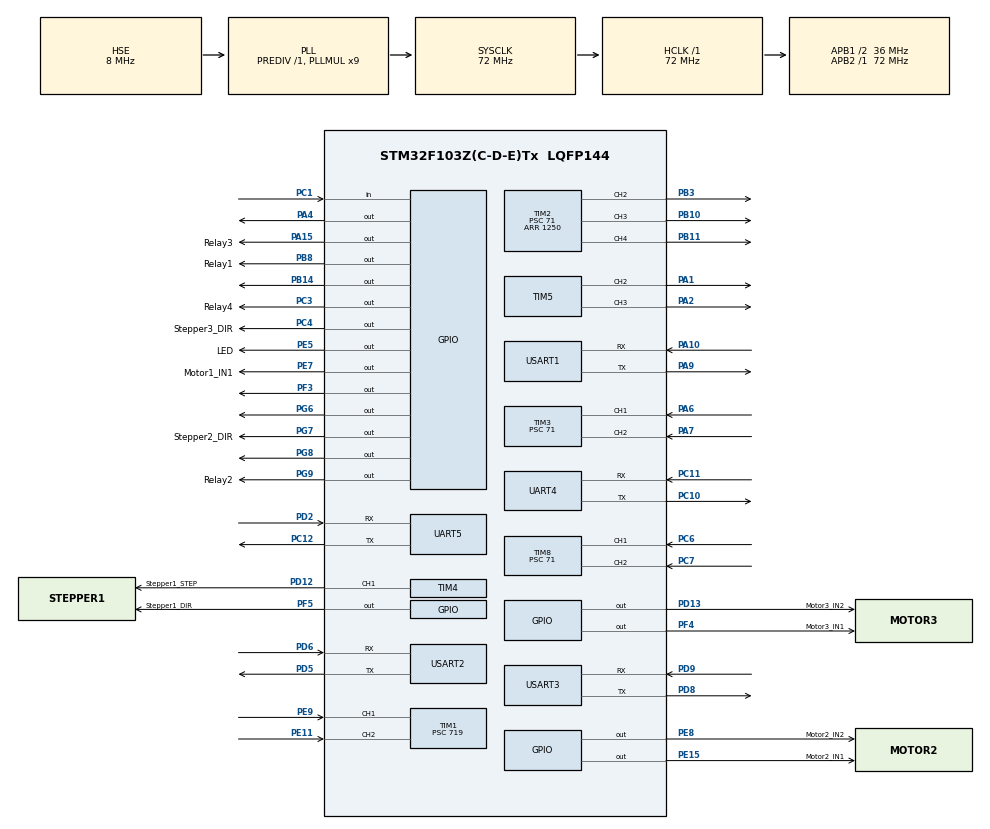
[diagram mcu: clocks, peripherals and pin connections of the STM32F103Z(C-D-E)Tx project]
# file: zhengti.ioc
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Mcu.Family=STM32F1
Mcu.Name=STM32F103Z(C-D-E)Tx
Mcu.Package=LQFP144
NVIC.PriorityGroup=NVIC_PRIORITYGROUP_4
NVIC.TIM2_IRQn=true\:0\:0\:false\:false\:true\:true\:true\:true
NVIC.TIM3_IRQn=true\:0\:0\:false\:false\:true\:true\:true\:true
NVIC.TIM4_IRQn=true\:0\:0\:false\:false\:true\:true\:true\:true
NVIC.TIM6_IRQn=true\:0\:0\:false\:false\:true\:true\:true\:true
NVIC.TIM7_IRQn=true\:0\:0\:false\:false\:true\:true\:true\:true
NVIC.TIM8_UP_IRQn=true\:0\:0\:false\:false\:true\:true\:true\:true
NVIC.USART1_IRQn=true\:0\:0\:false\:false\:true\:true\:true\:true
NVIC.USART2_IRQn=true\:0\:0\:false\:false\:true\:true\:true\:true
NVIC.USART3_IRQn=true\:0\:0\:false\:false\:true\:true\:true\:true
OSC_IN.Mode=HSE-External-Oscillator
OSC_IN.Signal=RCC_OSC_IN
OSC_OUT.Mode=HSE-External-Oscillator
OSC_OUT.Signal=RCC_OSC_OUT
PA1.Signal=S_TIM5_CH2
PA10.Mode=Asynchronous
PA10.Signal=USART1_RX
PA13.Mode=Serial_Wire
PA13.Signal=SYS_JTMS-SWDIO
PA14.Mode=Serial_Wire
PA14.Signal=SYS_JTCK-SWCLK
PA15.GPIO_Label=Relay3
PA15.Signal=GPIO_Output
PA2.Signal=S_TIM5_CH3
PA4.Signal=GPIO_Output
PA6.GPIO_PuPd=GPIO_PULLUP
PA6.Signal=S_TIM3_CH1
PA7.GPIO_PuPd=GPIO_PULLUP
PA7.Signal=S_TIM3_CH2
PA9.Mode=Asynchronous
PA9.Signal=USART1_TX
PB10.Signal=S_TIM2_CH3
PB11.Signal=S_TIM2_CH4
PB14.Signal=GPIO_Output
PB3.Signal=S_TIM2_CH2
PB8.GPIO_Label=Relay1
PB8.Signal=GPIO_Output
PC1.Signal=GPIO_Input
PC10.Mode=Asynchronous
PC10.Signal=UART4_TX
PC11.Mode=Asynchronous
PC11.Signal=UART4_RX
PC12.Mode=Asynchronous
PC12.Signal=UART5_TX
PC3.GPIO_Label=Relay4
PC3.Signal=GPIO_Output
PC4.GPIO_Label=Stepper3_DIR
PC4.Signal=GPIO_Output
PC6.GPIO_PuPd=GPIO_PULLUP
PC6.Signal=S_TIM8_CH1
PC7.GPIO_PuPd=GPIO_PULLUP
PC7.Signal=S_TIM8_CH2
PD12.GPIO_Label=Stepper1_STEP
PD12.Signal=S_TIM4_CH1
PD13.GPIO_Label=Motor3_IN2
PD13.Signal=GPIO_Output
PD2.Mode=Asynchronous
PD2.Signal=UART5_RX
PD5.Mode=Asynchronous
PD5.Signal=USART2_TX
PD6.Mode=Asynchronous
PD6.Signal=USART2_RX
PD8.Mode=Asynchronous
PD8.Signal=USART3_TX
PD9.Mode=Asynchronous
PD9.Signal=USART3_RX
PE11.GPIO_PuPd=GPIO_PULLUP
PE11.Signal=S_TIM1_CH2
PE15.GPIO_Label=Motor2_IN1
PE15.Signal=GPIO_Output
PE5.GPIO_Label=LED
PE5.Signal=GPIO_Output
PE7.GPIO_Label=Motor1_IN1
PE7.Signal=GPIO_Output
PE8.GPIO_Label=Motor2_IN2
PE8.Signal=GPIO_Output
PE9.GPIO_PuPd=GPIO_PULLUP
PE9.Signal=S_TIM1_CH1
PF3.Signal=GPIO_Output
PF4.GPIO_Label=Motor3_IN1
PF4.Signal=GPIO_Output
PF5.GPIO_Label=Stepper1_DIR
PF5.Signal=GPIO_Output
PG6.Signal=GPIO_Output
PG7.GPIO_Label=Stepper2_DIR
PG7.Signal=GPIO_Output
PG8.Signal=GPIO_Output
PG9.GPIO_Label=Relay2
PG9.Signal=GPIO_Output
ProjectManager.HeapSize=0x200
ProjectManager.StackSize=0x400
ProjectManager.TargetToolchain=MDK-ARM V5.32
RCC.AHBFreq_Value=72000000
RCC.APB1CLKDivider=RCC_HCLK_DIV2
RCC.APB1Freq_Value=36000000
RCC.APB1TimFreq_Value=72000000
RCC.APB2Freq_Value=72000000
RCC.APB2TimFreq_Value=72000000
RCC.HCLKFreq_Value=72000000
RCC.PLLMUL=RCC_PLL_MUL9
RCC.PLLSourceVirtual=RCC_PLLSOURCE_HSE
RCC.SYSCLKFreq_VALUE=72000000
RCC.SYSCLKSource=RCC_SYSCLKSOURCE_PLLCLK
RCC.USBFreq_Value=72000000
SH.S_TIM1_CH1.0=TIM1_CH1,Encoder_Interface
SH.S_TIM1_CH2.0=TIM1_CH2,Encoder_Interface
SH.S_TIM2_CH2.0=TIM2_CH2,PWM Generation2 CH2
SH.S_TIM2_CH3.0=TIM2_CH3,PWM Generation3 CH3
SH.S_TIM2_CH4.0=TIM2_CH4,PWM Generation4 CH4
SH.S_TIM3_CH1.0=TIM3_CH1,Encoder_Interface
SH.S_TIM3_CH2.0=TIM3_CH2,Encoder_Interface
SH.S_TIM4_CH1.0=TIM4_CH1,PWM Generation1 CH1
SH.S_TIM5_CH2.0=TIM5_CH2,PWM Generation2 CH2
SH.S_TIM5_CH3.0=TIM5_CH3,PWM Generation3 CH3
SH.S_TIM8_CH1.0=TIM8_CH1,Encoder_Interface
SH.S_TIM8_CH2.0=TIM8_CH2,Encoder_Interface
TIM1.Period=99
TIM1.Prescaler=719
TIM2.Channel-PWM\ Generation2\ CH2=TIM_CHANNEL_2
TIM2.Channel-PWM\ Generation3\ CH3=TIM_CHANNEL_3
TIM2.Channel-PWM\ Generation4\ CH4=TIM_CHANNEL_4
TIM2.Period=1250
TIM2.Prescaler=71
TIM2.Pulse-PWM\ Generation3\ CH3=625
TIM3.Period=625
TIM3.Prescaler=71
TIM4.AutoReloadPreload=TIM_AUTORELOAD_PRELOAD_ENABLE
TIM4.Channel-PWM\ Generation1\ CH1=TIM_CHANNEL_1
TIM4.Period=1000-1
TIM4.Prescaler=72-1
TIM4.Pulse-PWM\ Generation1\ CH1=500
TIM5.Channel-PWM\ Generation2\ CH2=TIM_CHANNEL_2
TIM5.Channel-PWM\ Generation3\ CH3=TIM_CHANNEL_3
TIM6.Period=9999
TIM6.Prescaler=7199
TIM7.Period=59999
TIM7.Prescaler=7199
TIM8.AutoReloadPreload=TIM_AUTORELOAD_PRELOAD_ENABLE
TIM8.Period=1250
TIM8.Prescaler=71
UART4.VirtualMode=Asynchronous
UART5.VirtualMode=Asynchronous
USART1.VirtualMode=VM_ASYNC
USART2.VirtualMode=VM_ASYNC
USART3.VirtualMode=VM_ASYNC
VP_TIM2_VS_ClockSourceINT.Mode=Internal
VP_TIM4_VS_ClockSourceINT.Mode=Internal
VP_TIM5_VS_ClockSourceINT.Mode=Internal
VP_TIM6_VS_ClockSourceINT.Mode=Enable_Timer
VP_TIM7_VS_ClockSourceINT.Mode=Enable_Timer
board=custom

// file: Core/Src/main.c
/* USER CODE BEGIN Header */
/**
  ******************************************************************************
  * @file           : main.c
  * @brief          : Main program body
  ******************************************************************************
  * @attention
  *
  * Copyright (c) 2026 STMicroelectronics.
  * All rights reserved.
  *
  * This software is licensed under terms that can be found in the LICENSE file
  * in the root directory of this software component.
  * If no LICENSE file comes with this software, it is provided AS-IS.
  *
  ******************************************************************************
  */
/* USER CODE END Header */
#include "main.h"
#include "tim.h"
#include "usart.h"
#include "gpio.h"

/* USER CODE BEGIN Includes */
#include "value.h"
#include "task.h"
/* USER CODE END Includes */

void SystemClock_Config(void);

int main(void)
{

  /* USER CODE BEGIN 1 */
  uint32_t tick;
  /* USER CODE END 1 */

  /* MCU Configuration--------------------------------------------------------*/

  /* Reset of all peripherals, Initializes the Flash interface and the Systick. */
  HAL_Init();

  /* Configure the system clock */
  SystemClock_Config();

  /* Initialize all configured peripherals */
  MX_GPIO_Init();
  MX_TIM1_Init();
  MX_TIM2_Init();
  MX_TIM3_Init();
  MX_TIM6_Init();
  MX_TIM7_Init();
  MX_TIM8_Init();
  MX_TIM4_Init();
  MX_USART1_UART_Init();
  MX_USART2_UART_Init();
  MX_USART3_UART_Init();
  MX_TIM5_Init();
  MX_UART4_Init();
  MX_UART5_Init();
  /* USER CODE BEGIN 2 */

  INIT_ALL();

  tick = HAL_GetTick();

  /* USER CODE END 2 */

  /* Infinite loop */
  /* USER CODE BEGIN WHILE */
  while (1)
  {
    /* 50Hz 任务调度 */
    if (HAL_GetTick() - tick < TASK_PERIOD_MS) continue;
    tick = HAL_GetTick();

    Task_Uart1();
    Task_Process();

    /* USER CODE END WHILE */

  }
}

void SystemClock_Config(void)
{
  RCC_OscInitTypeDef RCC_OscInitStruct = {0};
  RCC_ClkInitTypeDef RCC_ClkInitStruct = {0};

  /** Initializes the RCC Oscillators according to the specified parameters
  * in the RCC_OscInitTypeDef structure.
  */
  RCC_OscInitStruct.OscillatorType = RCC_OSCILLATORTYPE_HSE;
  RCC_OscInitStruct.HSEState = RCC_HSE_ON;
  RCC_OscInitStruct.HSEPredivValue = RCC_HSE_PREDIV_DIV1;
  RCC_OscInitStruct.HSIState = RCC_HSI_ON;
  RCC_OscInitStruct.PLL.PLLState = RCC_PLL_ON;
  RCC_OscInitStruct.PLL.PLLSource = RCC_PLLSOURCE_HSE;
  RCC_OscInitStruct.PLL.PLLMUL = RCC_PLL_MUL9;
  if (HAL_RCC_OscConfig(&RCC_OscInitStruct) != HAL_OK)
  {
    Error_Handler();
  }

  /** Initializes the CPU, AHB and APB buses clocks
  */
  RCC_ClkInitStruct.ClockType = RCC_CLOCKTYPE_HCLK|RCC_CLOCKTYPE_SYSCLK
                              |RCC_CLOCKTYPE_PCLK1|RCC_CLOCKTYPE_PCLK2;
  RCC_ClkInitStruct.SYSCLKSource = RCC_SYSCLKSOURCE_PLLCLK;
  RCC_ClkInitStruct.AHBCLKDivider = RCC_SYSCLK_DIV1;
  RCC_ClkInitStruct.APB1CLKDivider = RCC_HCLK_DIV2;
  RCC_ClkInitStruct.APB2CLKDivider = RCC_HCLK_DIV1;

  if (HAL_RCC_ClockConfig(&RCC_ClkInitStruct, FLASH_LATENCY_2) != HAL_OK)
  {
    Error_Handler();
  }
}

void Error_Handler(void)
{
  __disable_irq();
  while (1)
  {
  }
}
